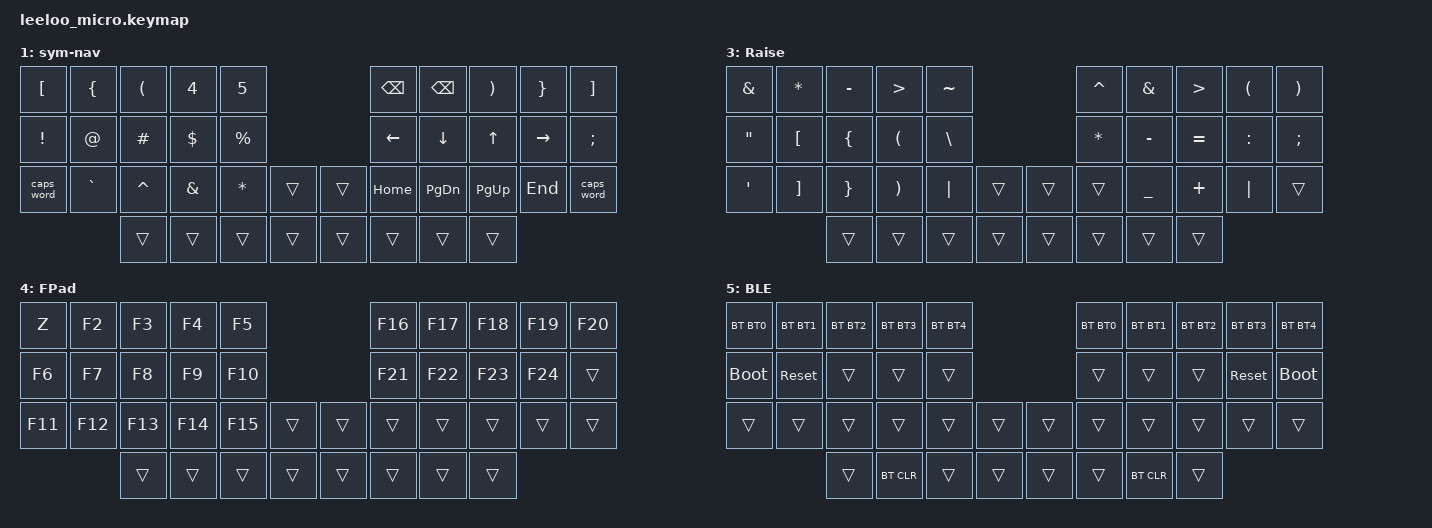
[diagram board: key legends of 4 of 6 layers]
/*
 * Copyright (c) 2023 The ZMK Contributors
 * SPDX-License-Identifier: MIT
 */

#include <behaviors.dtsi>
#include <dt-bindings/zmk/outputs.h>
#include <dt-bindings/zmk/keys.h>
#include <dt-bindings/zmk/bt.h>
#include <dt-bindings/zmk/rgb.h>



// Home row mods macro
// left shift causes a lot of misfirfes 
#define HRML(k1,k2,k3,k4) &kp k1  &mt LCTRL k2  &mt LALT  k3  &mt LGUI  k4
#define HRMR(k1,k2,k3,k4) &mt RGUI  k1  &mt RALT  k2  &mt RCTRL k3  &mt RSHFT k4


// Layers
#define QW_M    0       // Main
#define QW_L    1       // Lower
#define QW_R    2       // Raise
#define QW_A    3       // Adjust

#define QC_N    4       // Number Pad
#define QC_B    5       // Firmware


// Short versions
#define BT0         BT_SEL 0
#define BT1         BT_SEL 1
#define BT2         BT_SEL 2
#define BT3         BT_SEL 3
#define BT4         BT_SEL 4

#define BOOTLDR     &bootloader

#define RGBON   &rgb_ug RGB_ON
#define RGBOFF  &rgb_ug RGB_OFF
#define RGBTOG  &rgb_ug RGB_TOG
#define RGBHUI  &rgb_ug RGB_HUI
#define RGBHUD  &rgb_ug RGB_HUD
#define RGBSAI  &rgb_ug RGB_SAI
#define RGBSAD  &rgb_ug RGB_SAD
#define RGBBRI  &rgb_ug RGB_BRI
#define RGBBRD  &rgb_ug RGB_BRD
#define RGBEFF  &rgb_ug RGB_EFF



/*
 * Assign the cs-gpios pin to 4.
 * Uncomment these next few lines if implementing nice!view Displays.
 */
//nice_view_spi: &spi0 {
//  cs-gpios = <&pro_micro 4 GPIO_ACTIVE_HIGH>;
//};


/ {
    conditional_layers {
        compatible = "zmk,conditional-layers";
        adjust_layer {
            if-layers = <QW_L QW_R>;
            then-layer = <QW_A>;
        };
    };

    combos {
        compatible = "zmk,combos";

        combo_esc {
            timeout-ms = <50>;
            key-positions = <0 1>;
            layers = <QW_M>;
            bindings = <&kp ESC>;
        };
    };

    keymap {
        compatible = "zmk,keymap";

// 0 
    default_layer {
            display-name = " QWERTY";
            bindings = <

        //╭──────────┬──────────┬──────────┬──────────┬──────────╮                       ╭──────────┬──────────┬──────────┬──────────┬──────────╮
        //│ Q (f pad)│  W       │  E       │  R       │  T       │                       │  Y       │  U       │  I       │  O       │   P      │           
        //├──────────┼──────────┼──────────┼──────────┼──────────┤                       ├──────────┼──────────┼──────────┼──────────┼──────────┤
        //│  A       │  S       │  D       │  F       │  G       │                       │  H       │  J       │  K       │  L       │   ;      │            
        //├──────────┼──────────┼──────────┼──────────┼──────────┤                       ├──────────┼──────────┼──────────┼──────────┼──────────┤
        //│  Z       │  X       │  C       │  V       │  B       │                       │  N       │  M       │ , <      │ . >      │ /?(enter)│ 
        //╰──────────┼──────────┼──────────┼──────────┼──────────┤                       ├──────────┼──────────┼──────────┴──────────┴──────────╯
        //           |          |          │ left/TAB │  SPACE   │                       │   SHIFT  │right/bspc|          |          │
        //           ╰──────────┴──────────┴──────────┴──────────╯                       ╰──────────┴──────────┴──────────┴──────────╯

            &kp Q       &kp W      &kp E      &kp R      &kp T                                 &kp Y      &kp U      &kp I      &kp O      &kp P
            HRML(A,     S,         D,         F)         &kp G                                 &kp H      HRMR(J,    K,          L,       SEMI)
            &mt LSHFT Z &kp X      &kp C      &kp V      &kp B      &mo 3          &mo 3       &kp N      &kp M      &kp COMMA  &kp DOT    &mt RSHFT FSLH
                                   &mo 2      &mo 3  &lt 4 TAB  &lt 5 SPACE    &lt 3 RET   &lt 1 SPACE  &kp BSPC   &mo QC_B
            >;
            sensor-bindings = <&inc_dec_kp C_VOL_DN C_VOL_UP>;
        };


// 1
right_layer {
            display-name = " sym-nav";
            bindings = <
        //╭──────────┬──────────┬──────────┬──────────┬──────────╮                ╭──────────┬──────────┬──────────┬──────────┬──────────╮
        //│    [     │    {     │    (     │     4    │     5    │                │   BSPC   │  BSPC    │     )    │    }     │     ]    │
        //├──────────┼──────────┼──────────┼──────────┼──────────┤                ├──────────┼──────────┼──────────┼──────────┼──────────┤
        //│      !   │    @     │   #      │    $     │    %     │                │   left   │  down    │    up    │  right   │   ;      │
        //├──────────┼──────────┼──────────┼──────────┼──────────┤                ├──────────┼──────────┼──────────┼──────────┼──────────┤
        //│ CAP word │    `~    │    ^     │    &     │    *     │                │   HOME   │ PG DN    │   PG UP  │   END    │ CAP word │
        //╰──────────┼──────────┼──────────┼──────────┼──────────┤                ├──────────┼──────────┼──────────┴──────────┴──────────╯                          
        //           |          |          │          │          │                │          │          |          |          │
        //           ╰──────────┴──────────┴──────────┴──────────╯                ╰──────────┴──────────┴──────────┴──────────╯

        
        &kp LBKT     &kp LBRC    &kp LPAR    &kp N4     &kp N5                      &kp BSPC    &kp BSPC   &kp RPAR   &kp RBRC   &kp RBKT
        &kp EXCL     &kp AT      &kp HASH    &kp DLLR   &kp PRCNT                   &kp LEFT    &kp DOWN   &kp UP     &kp RIGHT  &kp SEMI
        &caps_word   &kp GRAVE   &kp CARET   &kp AMPS   &kp ASTRK  &trans   &trans  &kp HOME    &kp PG_DN  &kp PG_UP  &kp END    &caps_word
                               &trans       &trans      &trans     &trans   &trans  &trans     &trans     &trans
            >; 
            sensor-bindings = <&inc_dec_kp C_VOL_DN C_VOL_UP>;
        };



// 3 
num_layer {
        display-name = " NumPad";
        bindings = <
        
        //╭──────────┬──────────┬──────────┬──────────┬──────────╮                 ╭──────────┬──────────┬──────────┬──────────┬──────────╮
        //│   del    │    1     │    2     │     3    │   0      │                 │  Vol Up  │          │          │          │          │
        //├──────────┼──────────┼──────────┼──────────┼──────────┤                 ├──────────┼──────────┼──────────┼──────────┼──────────┤
        //│          │    4     │    5     │     6    │          │                 │  Vol Dwn │          │          │          │          │
        //├──────────┼──────────┼──────────┼──────────┼──────────┤                 ├──────────┼──────────┼──────────┼──────────┼──────────┤
        //│          │    7     │   8      │     9    │          │                 │  Mute    │          │          │          │          │
        //╰──────────┴──────────┴──────────┼──────────┼──────────┤                 ├──────────┼──────────┼──────────┴──────────┴──────────╯
        //                                 ╰──────────┴──────────╯                 ╰──────────┴──────────╯
                      
        &kp DEL      &kp N1     &kp N2    &kp N3     &kp N0                         &kp C_VOL_UP  &kp LPAR   &kp RPAR   &trans    &trans
        &trans       &kp N4     &kp N5    &kp N6     &trans                         &kp C_VOL_DN  &kp LBRC   &kp RBRC   &trans    &trans
        &trans       &kp N7     &kp N8    &kp N9     &trans  &trans        &trans   &kp C_MUTE    &trans     &trans     &trans    &trans
                                          &trans     &trans  &trans        &trans   &trans        &trans


        >;
            sensor-bindings = <&inc_dec_kp C_VOL_DN C_VOL_UP>;
        };



// 2
left_layer {
            display-name = " Raise";
            bindings = <
        //╭──────────┬──────────┬──────────┬──────────┬──────────╮                 ╭──────────┬──────────┬──────────┬──────────┬──────────╮
        //│    &     │    *     │    -     │     >    │    ~     │                 │  ^       │    &     │    >     │    (     │    )     │
        //├──────────┼──────────┼──────────┼──────────┼──────────┤                 ├──────────┼──────────┼──────────┼──────────┼──────────┤
        //│    "     │    [     │    {     │    (     │   \      │                 │  *       │  -       │  =       │    :     │   ;      │
        //├──────────┼──────────┼──────────┼──────────┼──────────┤                 ├──────────┼──────────┼──────────┼──────────┼──────────┤
        //│    '     │    ]     │    }     │    )     │   |      │                 │  (n)     │  _       │  +       │  │       │          │
        //╰──────────┴──────────┴──────────┼──────────┼──────────┤                 ├──────────┼──────────┼──────────┴──────────┴──────────╯
        //                                 ╰──────────┴──────────╯                 ╰──────────┴──────────╯
                      
        &kp AMPS   &kp STAR   &kp MINUS   &kp GT     &kp TILDE                      &kp CARET   &kp AMPS   &kp GT     &kp LPAR   &kp RPAR
        &kp DQT    &kp LBKT   &kp LBRC    &kp LPAR   &kp BSLH                       &kp ASTRK   &kp MINUS  &kp EQUAL  &kp COLON  &kp SEMI
        &kp SQT    &kp RBKT   &kp RBRC    &kp RPAR   &kp PIPE   &trans     &trans   &trans      &kp UNDER  &kp PLUS   &kp PIPE   &trans
                              &trans      &trans     &trans     &trans     &trans   &trans      &trans     &trans
            >;  
            sensor-bindings = <&inc_dec_kp C_VOL_DN C_VOL_UP>;
        };

// 4 
adjust_layer {
            display-name = " FPad";
            bindings = <

            &kp Z      &kp F2     &kp F3     &kp F4     &kp F5                           &kp F16     &kp F17   &kp F18    &kp F19    &kp F20
            &kp F6     &kp F7     &kp F8     &kp F9     &kp F10                          &kp F21     &kp F22   &kp F23    &kp F24     &trans
            &kp F11    &kp F12    &kp F13    &kp F14    &kp F15    &trans     &trans     &trans     &trans     &trans     &trans     &trans
                       &trans     &trans     &trans     &trans     &trans     &trans     &trans     &trans
            >;

            sensor-bindings = <&inc_dec_kp C_VOL_DN C_VOL_UP>;
        };


// 4
ble_layer {
            display-name = " BLE";
            bindings = <

            &bt BT0    &bt BT1    &bt BT2    &bt BT3    &bt BT4                          &bt BT0    &bt BT1    &bt BT2    &bt BT3    &bt BT4
            BOOTLDR    &sys_reset &trans     &trans     &trans                           &trans     &trans     &trans     &sys_reset BOOTLDR
            &trans     &trans     &trans     &trans     &trans     &trans     &trans     &trans     &trans     &trans     &trans     &trans
                      &trans     &bt BT_CLR &trans     &trans      &trans     &trans     &bt BT_CLR &trans
            >;
            sensor-bindings = <&inc_dec_kp C_VOL_DN C_VOL_UP>;
        };
    };
};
